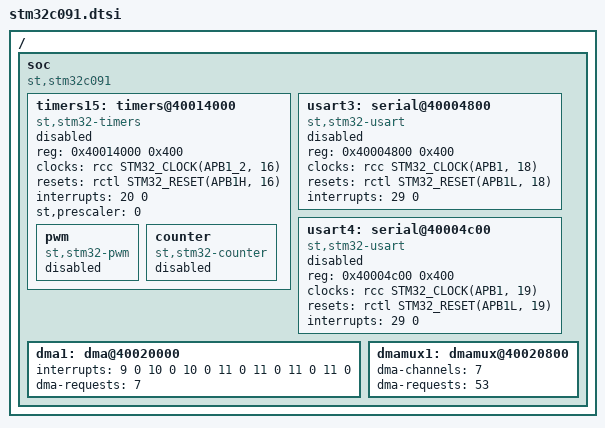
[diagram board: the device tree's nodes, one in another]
/*
 * Copyright (c) 2025 Thomas Stranger
 *
 * SPDX-License-Identifier: Apache-2.0
 */

#include <st/c0/stm32c051.dtsi>

/ {
	soc {
		compatible = "st,stm32c091", "st,stm32c0", "simple-bus";

		timers15: timers@40014000 {
			compatible = "st,stm32-timers";
			reg = <0x40014000 0x400>;
			clocks = <&rcc STM32_CLOCK(APB1_2, 16)>;
			resets = <&rctl STM32_RESET(APB1H, 16)>;
			interrupts = <20 0>;
			interrupt-names = "global";
			st,prescaler = <0>;
			status = "disabled";

			pwm {
				compatible = "st,stm32-pwm";
				status = "disabled";
				#pwm-cells = <3>;
			};

			counter {
				compatible = "st,stm32-counter";
				status = "disabled";
			};
		};

		usart3: serial@40004800 {
			compatible = "st,stm32-usart", "st,stm32-uart";
			reg = <0x40004800 0x400>;
			clocks = <&rcc STM32_CLOCK(APB1, 18)>;
			resets = <&rctl STM32_RESET(APB1L, 18)>;
			interrupts = <29 0>;
			status = "disabled";
		};

		usart4: serial@40004c00 {
			compatible = "st,stm32-usart", "st,stm32-uart";
			reg = <0x40004c00 0x400>;
			clocks = <&rcc STM32_CLOCK(APB1, 19)>;
			resets = <&rctl STM32_RESET(APB1L, 19)>;
			interrupts = <29 0>;
			status = "disabled";
		};

		dma1: dma@40020000 {
			interrupts = <9 0 10 0 10 0 11 0 11 0 11 0 11 0>;
			dma-requests = <7>;
		};

		dmamux1: dmamux@40020800 {
			dma-channels = <7>;
			dma-requests = <53>;
		};
	};
};
